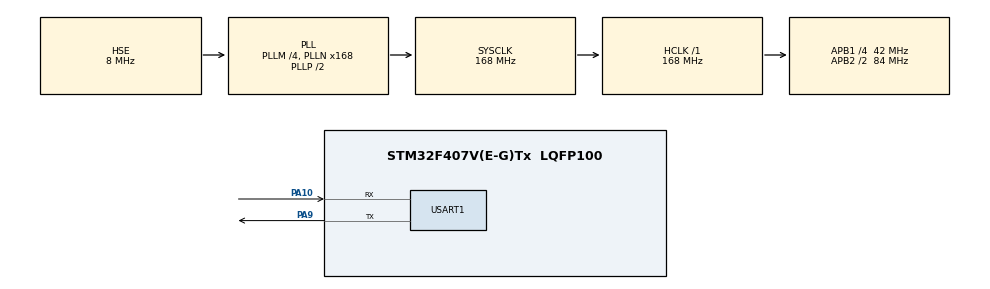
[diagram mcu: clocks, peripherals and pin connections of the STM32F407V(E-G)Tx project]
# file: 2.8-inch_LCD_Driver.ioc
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Dma.Request0=USART1_RX
Dma.Request1=USART1_TX
Dma.USART1_RX.0.Direction=DMA_PERIPH_TO_MEMORY
Dma.USART1_RX.0.FIFOMode=DMA_FIFOMODE_DISABLE
Dma.USART1_RX.0.Instance=DMA2_Stream2
Dma.USART1_RX.0.MemDataAlignment=DMA_MDATAALIGN_BYTE
Dma.USART1_RX.0.MemInc=DMA_MINC_ENABLE
Dma.USART1_RX.0.Mode=DMA_CIRCULAR
Dma.USART1_RX.0.PeriphDataAlignment=DMA_PDATAALIGN_BYTE
Dma.USART1_RX.0.PeriphInc=DMA_PINC_DISABLE
Dma.USART1_RX.0.Priority=DMA_PRIORITY_LOW
Dma.USART1_TX.1.Direction=DMA_MEMORY_TO_PERIPH
Dma.USART1_TX.1.FIFOMode=DMA_FIFOMODE_DISABLE
Dma.USART1_TX.1.Instance=DMA2_Stream7
Dma.USART1_TX.1.MemDataAlignment=DMA_MDATAALIGN_BYTE
Dma.USART1_TX.1.MemInc=DMA_MINC_ENABLE
Dma.USART1_TX.1.Mode=DMA_NORMAL
Dma.USART1_TX.1.PeriphDataAlignment=DMA_PDATAALIGN_BYTE
Dma.USART1_TX.1.PeriphInc=DMA_PINC_DISABLE
Dma.USART1_TX.1.Priority=DMA_PRIORITY_LOW
Mcu.Family=STM32F4
Mcu.Name=STM32F407V(E-G)Tx
Mcu.Package=LQFP100
NVIC.DMA2_Stream2_IRQn=true\:0\:0\:false\:false\:true\:false\:true\:true
NVIC.DMA2_Stream7_IRQn=true\:0\:0\:false\:false\:true\:false\:true\:true
NVIC.PriorityGroup=NVIC_PRIORITYGROUP_4
NVIC.USART1_IRQn=true\:0\:0\:false\:false\:true\:true\:true\:true
PA10.Mode=Asynchronous
PA10.Signal=USART1_RX
PA13.Mode=Serial_Wire
PA13.Signal=SYS_JTMS-SWDIO
PA14.Mode=Serial_Wire
PA14.Signal=SYS_JTCK-SWCLK
PA9.Mode=Asynchronous
PA9.Signal=USART1_TX
PH0-OSC_IN.Mode=HSE-External-Oscillator
PH0-OSC_IN.Signal=RCC_OSC_IN
PH1-OSC_OUT.Mode=HSE-External-Oscillator
PH1-OSC_OUT.Signal=RCC_OSC_OUT
ProjectManager.HeapSize=0x200
ProjectManager.StackSize=0x400
ProjectManager.TargetToolchain=CMake
RCC.48MHZClocksFreq_Value=84000000
RCC.AHBFreq_Value=168000000
RCC.APB1CLKDivider=RCC_HCLK_DIV4
RCC.APB1Freq_Value=42000000
RCC.APB1TimFreq_Value=84000000
RCC.APB2CLKDivider=RCC_HCLK_DIV2
RCC.APB2Freq_Value=84000000
RCC.APB2TimFreq_Value=168000000
RCC.CortexFreq_Value=168000000
RCC.HCLKFreq_Value=168000000
RCC.HSE_VALUE=8000000
RCC.HSI_VALUE=16000000
RCC.LSE_VALUE=32768
RCC.PLLM=4
RCC.PLLN=168
RCC.PLLSourceVirtual=RCC_PLLSOURCE_HSE
RCC.SYSCLKFreq_VALUE=168000000
RCC.SYSCLKSource=RCC_SYSCLKSOURCE_PLLCLK
RCC.VCOOutputFreq_Value=336000000
USART1.VirtualMode=VM_ASYNC
board=custom

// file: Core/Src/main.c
/* USER CODE BEGIN Header */
/**
  ******************************************************************************
  * @file           : main.c
  * @brief          : Main program body
  ******************************************************************************
  * @attention
  *
  * Copyright (c) 2026 STMicroelectronics.
  * All rights reserved.
  *
  * This software is licensed under terms that can be found in the LICENSE file
  * in the root directory of this software component.
  * If no LICENSE file comes with this software, it is provided AS-IS.
  *
  ******************************************************************************
  */
/* USER CODE END Header */
#include "main.h"

/* USER CODE BEGIN Includes */
#include "uart.h"
#include "usart.h"
#include "lcd.h"
#include "touch.h"
#include "self_test.h"
#include "app_boot_interface.h"
#include "image2.h"
#include "image3.h"
#include <string.h>
#include <stdio.h>
/* USER CODE END Includes */

/* USER CODE BEGIN PD */
/* 上电自检: 1=初始化完成后执行 LCD/TP/UART 自检 (结果经串口输出) */
#define SELF_TEST_ENABLE 0
/* USER CODE END PD */

UART_HandleTypeDef huart1;
DMA_HandleTypeDef hdma_usart1_rx;
DMA_HandleTypeDef hdma_usart1_tx;

/* USER CODE BEGIN PV */
static uint32_t g_last_hello = 0;
static uint8_t  g_img_idx = 0;
static const u16 * const IMAGES[] = { test2_image, test3_image };
/* USER CODE END PV */

void SystemClock_Config(void);
static void MX_GPIO_Init(void);
static void MX_DMA_Init(void);
static void MX_USART1_UART_Init(void);

/* USER CODE BEGIN 0 */
/* 串口命令缓冲: 收到 "dfu"/"boot" 回车后进入 Bootloader */
#define CMD_BUF_SIZE 16
static char     g_cmd_buf[CMD_BUF_SIZE];
static uint8_t  g_cmd_len = 0;

/* DMA 中断回传: 逐字节回调, 把收到的数据原样发回 */
static void echo_rx_cb(UART_Port port, uint8_t *data, uint16_t len) {
    uint16_t w;
    uint16_t i;
    for (i = 0; i < len; i++) {
        char c = (char)data[i];
        if (c == '\r' || c == '\n') {
            if (g_cmd_len > 0) {
                g_cmd_buf[g_cmd_len] = 0;
                g_cmd_len = 0;
                if (strcmp(g_cmd_buf, "dfu") == 0 || strcmp(g_cmd_buf, "boot") == 0) {
                    APP_JumpToBootloader();   /* 软复位进 BL, 等待编程器 */
                }
            }
        } else if (g_cmd_len < CMD_BUF_SIZE - 1) {
            g_cmd_buf[g_cmd_len++] = c;
        }
    }
    UART_Send(port, data, len, &w);
}
/* USER CODE END 0 */

int main(void)
{

  /* USER CODE BEGIN 1 */
  /* App 运行在 Bootloader 之后 (0x08008000): 必须先设向量表, 再 HAL_Init */
  APP_SetVectorTable();
  /* USER CODE END 1 */

  /* MCU Configuration--------------------------------------------------------*/

  /* Reset of all peripherals, Initializes the Flash interface and the Systick. */
  HAL_Init();

  /* Configure the system clock */
  SystemClock_Config();

  /* Initialize all configured peripherals */
  MX_GPIO_Init();
  MX_DMA_Init();
  MX_USART1_UART_Init();
  /* USER CODE BEGIN 2 */

  /* 通用串口库: 注册并打开 USART1 (RX DMA CIRCULAR + IDLE, TX DMA 链式) */
  UART_Init();
  if (UART_Open(UART_P1) != UART_OK) {
      Error_Handler();
  }

  /* 注册 DMA 中断回传帧 (header_len=0 → 逐字节回调) */
  static UART_Frame echo_frame = {
      .header_len = 0,
      .callback   = echo_rx_cb,
  };
  UART_RegisterFrame(UART_P1, &echo_frame);

  /* LCD 显示驱动: FSMC + 控制器初始化 */
  LCD_Init();
  {
      uint16_t w;
      char dbg[48];
      int n = sprintf(dbg, "Final ID=%04X\r\n", (unsigned)lcddev.id);
      UART_Send(UART_P1, (const uint8_t *)dbg, (uint16_t)n, &w);
  }
  POINT_COLOR = RED;
  LCD_Clear(BLACK);
  LCD_ShowString(20, 20, 200, 16, 16, "LCD Driver OK");
  LCD_ShowString(20, 40, 200, 16, 16, "mcudev 2.8 TFT");
  {
      char buf[16];
      sprintf(buf, "ID:%04X", (unsigned)lcddev.id);
      LCD_ShowString(20, 60, 120, 16, 16, buf);
  }

  /* 触摸屏: 使用预存校准值, 不再弹四角校准 */
  TP_Init();
  LCD_ShowString(20, 80, 200, 16, 16, "Touch calibrated");

  /* 上电自检 (SELF_TEST_ENABLE=1 时执行, 结果经串口输出) */
#if (SELF_TEST_ENABLE == 1)
  LIB_SelfTest(UART_P1);
#endif

  LCD_ShowString(20, 100, 200, 16, 16, "Touch to switch img");

  /* 显示第一张图 */
  LCD_ShowImage(0, 0, 240, 320, IMAGES[0]);

  g_last_hello = HAL_GetTick();
  /* USER CODE END 2 */

  /* Infinite loop */
  while (1)
  {

    /* USER CODE BEGIN 3 */
    /* 串口任务: 环形缓冲 → 帧解析 → 回传回调 */
    UART_Task();

    /* 触摸手势 (上层只消费手势事件): 单击切图, 长按白屏, 滑动提示 */
    switch (TP_GetGesture()) {
    case TOUCH_EVENT_SINGLE_CLICK:
        g_img_idx = (uint8_t)((g_img_idx + 1) % (sizeof(IMAGES) / sizeof(IMAGES[0])));
        LCD_ShowImage(0, 0, lcddev.width, lcddev.height, IMAGES[g_img_idx]);
        break;
    case TOUCH_EVENT_LONG_PRESS:
        LCD_Clear(WHITE);
        break;
    case TOUCH_EVENT_SWIPE:
        POINT_COLOR = RED;
        LCD_ShowString(20, 300, 200, 16, 16, "Swipe!");
        break;
    default:
        break;
    }

    /* 定时发送 hello (每 1s) */
    if (HAL_GetTick() - g_last_hello >= 1000) {
        g_last_hello = HAL_GetTick();
        uint16_t w;
        UART_Send(UART_P1, (const uint8_t *)"hello\r\n", 7, &w);
    }
  }
  /* USER CODE END 3 */
}

void SystemClock_Config(void)
{
  RCC_OscInitTypeDef RCC_OscInitStruct = {0};
  RCC_ClkInitTypeDef RCC_ClkInitStruct = {0};

  /** Configure the main internal regulator output voltage
  */
  __HAL_RCC_PWR_CLK_ENABLE();
  __HAL_PWR_VOLTAGESCALING_CONFIG(PWR_REGULATOR_VOLTAGE_SCALE1);

  /** Initializes the RCC Oscillators according to the specified parameters
  * in the RCC_OscInitTypeDef structure.
  */
  RCC_OscInitStruct.OscillatorType = RCC_OSCILLATORTYPE_HSE;
  RCC_OscInitStruct.HSEState = RCC_HSE_ON;
  RCC_OscInitStruct.PLL.PLLState = RCC_PLL_ON;
  RCC_OscInitStruct.PLL.PLLSource = RCC_PLLSOURCE_HSE;
  RCC_OscInitStruct.PLL.PLLM = 4;
  RCC_OscInitStruct.PLL.PLLN = 168;
  RCC_OscInitStruct.PLL.PLLP = RCC_PLLP_DIV2;
  RCC_OscInitStruct.PLL.PLLQ = 4;
  if (HAL_RCC_OscConfig(&RCC_OscInitStruct) != HAL_OK)
  {
    Error_Handler();
  }

  /** Initializes the CPU, AHB and APB buses clocks
  */
  RCC_ClkInitStruct.ClockType = RCC_CLOCKTYPE_HCLK|RCC_CLOCKTYPE_SYSCLK
                              |RCC_CLOCKTYPE_PCLK1|RCC_CLOCKTYPE_PCLK2;
  RCC_ClkInitStruct.SYSCLKSource = RCC_SYSCLKSOURCE_PLLCLK;
  RCC_ClkInitStruct.AHBCLKDivider = RCC_SYSCLK_DIV1;
  RCC_ClkInitStruct.APB1CLKDivider = RCC_HCLK_DIV4;
  RCC_ClkInitStruct.APB2CLKDivider = RCC_HCLK_DIV2;

  if (HAL_RCC_ClockConfig(&RCC_ClkInitStruct, FLASH_LATENCY_5) != HAL_OK)
  {
    Error_Handler();
  }
}

static void MX_USART1_UART_Init(void)
{

  huart1.Instance = USART1;
  huart1.Init.BaudRate = 115200;
  huart1.Init.WordLength = UART_WORDLENGTH_8B;
  huart1.Init.StopBits = UART_STOPBITS_1;
  huart1.Init.Parity = UART_PARITY_NONE;
  huart1.Init.Mode = UART_MODE_TX_RX;
  huart1.Init.HwFlowCtl = UART_HWCONTROL_NONE;
  huart1.Init.OverSampling = UART_OVERSAMPLING_16;
  if (HAL_UART_Init(&huart1) != HAL_OK)
  {
    Error_Handler();
  }

}

static void MX_DMA_Init(void)
{

  /* DMA controller clock enable */
  __HAL_RCC_DMA2_CLK_ENABLE();

  /* DMA interrupt init */
  /* DMA2_Stream2_IRQn interrupt configuration */
  HAL_NVIC_SetPriority(DMA2_Stream2_IRQn, 0, 0);
  HAL_NVIC_EnableIRQ(DMA2_Stream2_IRQn);
  /* DMA2_Stream7_IRQn interrupt configuration */
  HAL_NVIC_SetPriority(DMA2_Stream7_IRQn, 0, 0);
  HAL_NVIC_EnableIRQ(DMA2_Stream7_IRQn);

}

static void MX_GPIO_Init(void)
{

  /* GPIO Ports Clock Enable */
  __HAL_RCC_GPIOH_CLK_ENABLE();
  __HAL_RCC_GPIOC_CLK_ENABLE();
  __HAL_RCC_GPIOB_CLK_ENABLE();
  __HAL_RCC_GPIOE_CLK_ENABLE();
  __HAL_RCC_GPIOD_CLK_ENABLE();
  __HAL_RCC_GPIOA_CLK_ENABLE();

}

void Error_Handler(void)
{
  __disable_irq();
  while (1)
  {
  }
}
